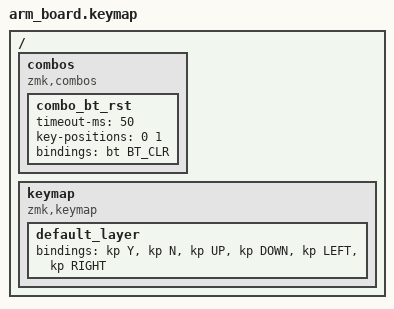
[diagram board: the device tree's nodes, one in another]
#include <behaviors.dtsi>
#include <dt-bindings/zmk/keys.h>
#include <dt-bindings/zmk/bt.h>

/ {
    combos {
        compatible = "zmk,combos";
        combo_bt_rst {
            timeout-ms = <50>;
            key-positions = <0 1>;
            bindings = <&bt BT_CLR>;
        };
    };
};

/ {
    keymap {
        compatible = "zmk,keymap";

        default_layer {
// --------------------------------------------------------------------------------------------------------------------------------------------------------------------
// |   Y   |    N    |    3    |    4    |    5    |    6    |
            bindings = <
    &kp  Y   &kp   N   &kp   UP   &kp   DOWN   &kp   LEFT    &kp   RIGHT
            >;
        };
    };
};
